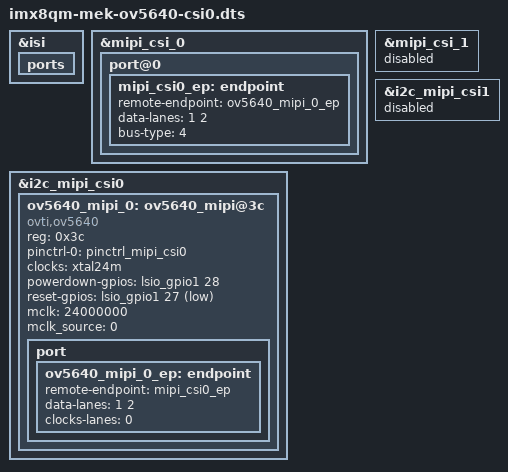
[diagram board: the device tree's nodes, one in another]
// SPDX-License-Identifier: GPL-2.0+
// Copyright NXP 2024

#include "imx8qm-mek.dts"

&isi {
	ports {
		/delete-node/port@3;
	};
};

&mipi_csi_0 {
	/delete-property/virtual-channel;

	/* Camera 0  MIPI CSI-2 (CSIS0) */
	port@0 {
		mipi_csi0_ep: endpoint {
			remote-endpoint = <&ov5640_mipi_0_ep>;
			data-lanes = <1 2>;
			bus-type = <4>;
		};
	};
};

&i2c_mipi_csi0 {
	ov5640_mipi_0: ov5640_mipi@3c {
		compatible = "ovti,ov5640";
		reg = <0x3c>;
		pinctrl-names = "default";
		pinctrl-0 = <&pinctrl_mipi_csi0>;
		clocks = <&xtal24m>;
		clock-names = "xclk";
		powerdown-gpios = <&lsio_gpio1 28 GPIO_ACTIVE_HIGH>;
		reset-gpios = <&lsio_gpio1 27 GPIO_ACTIVE_LOW>;
		mclk = <24000000>;
		mclk_source = <0>;
		status = "okay";

		port {
			ov5640_mipi_0_ep: endpoint {
				remote-endpoint = <&mipi_csi0_ep>;
				data-lanes = <1 2>;
				clocks-lanes = <0>;
			};
		};
	};

	/delete-node/max9286_mipi@6a;
};

&mipi_csi_1 {
	status = "disabled";
	/delete-node/port@0;
	/delete-node/port@1;
};

&i2c_mipi_csi1 {
	status = "disabled";
	/delete-node/max9286_mipi@6a;
};
